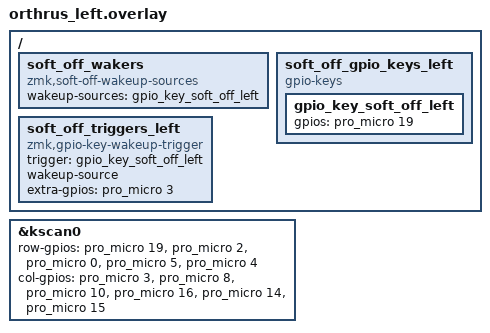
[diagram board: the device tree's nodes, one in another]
#include "orthrus.dtsi"

&kscan0 {
    row-gpios
        = <&pro_micro 19 (GPIO_ACTIVE_HIGH | GPIO_PULL_DOWN)> // Row 0 (P002)
        , <&pro_micro 2  (GPIO_ACTIVE_HIGH | GPIO_PULL_DOWN)> // Row 1 (P017)
        , <&pro_micro 0  (GPIO_ACTIVE_HIGH | GPIO_PULL_DOWN)> // Row 2 (P008)
        , <&pro_micro 5  (GPIO_ACTIVE_HIGH | GPIO_PULL_DOWN)> // Row 3 (P024)
        , <&pro_micro 4  (GPIO_ACTIVE_HIGH | GPIO_PULL_DOWN)> // Row 4 (P022)
        ;

    col-gpios
        = <&pro_micro 3  GPIO_ACTIVE_HIGH> // P020
        , <&pro_micro 8  GPIO_ACTIVE_HIGH> // P104
        , <&pro_micro 10 GPIO_ACTIVE_HIGH> // P009
        , <&pro_micro 16 GPIO_ACTIVE_HIGH> // P010
        , <&pro_micro 14 GPIO_ACTIVE_HIGH> // P111
        , <&pro_micro 15 GPIO_ACTIVE_HIGH> // P113
        ;
};

/ {
    soft_off_wakers {
        compatible = "zmk,soft-off-wakeup-sources";
        wakeup-sources = <&gpio_key_soft_off_left>;
    };

    soft_off_gpio_keys_left {
        compatible = "gpio-keys";
        gpio_key_soft_off_left: gpio_key_soft_off_left {
            gpios = <&pro_micro 19 (GPIO_ACTIVE_HIGH | GPIO_PULL_DOWN)>;
        };
    };

    soft_off_triggers_left {
        compatible = "zmk,gpio-key-wakeup-trigger";
        trigger = <&gpio_key_soft_off_left>;
        wakeup-source;
        extra-gpios = <&pro_micro 3 GPIO_ACTIVE_HIGH>;
    };
};
